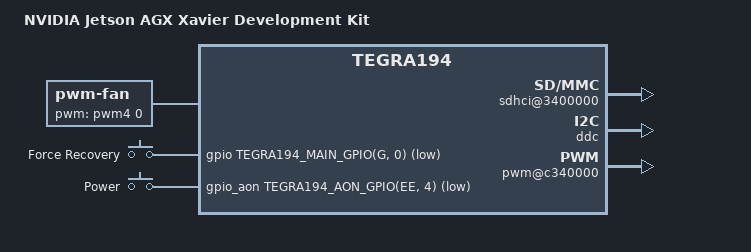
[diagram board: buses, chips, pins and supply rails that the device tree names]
// SPDX-License-Identifier: GPL-2.0
/dts-v1/;

#include <dt-bindings/input/linux-event-codes.h>
#include <dt-bindings/input/gpio-keys.h>

#include "tegra194-p2888.dtsi"

/ {
	model = "NVIDIA Jetson AGX Xavier Development Kit";
	compatible = "nvidia,p2972-0000", "nvidia,tegra194";

	cbb {
		/* SDMMC1 (SD/MMC) */
		sdhci@3400000 {
			status = "okay";
		};

		host1x@13e00000 {
			display-hub@15200000 {
				status = "okay";
			};

			dpaux@155e0000 {
				status = "okay";
			};

			sor@15b80000 {
				status = "okay";

				avdd-io-supply = <&vdd_1v0>;
				vdd-pll-supply = <&vdd_1v8hs>;
				hdmi-supply = <&vdd_hdmi>;

				nvidia,ddc-i2c-bus = <&ddc>;
				nvidia,hpd-gpio = <&gpio TEGRA194_MAIN_GPIO(M, 2) GPIO_ACTIVE_LOW>;
			};
		};

		ddc: i2c@31c0000 {
			status = "okay";
		};

		pwm@c340000 {
			status = "okay";
		};
	};

	fan {
		compatible = "pwm-fan";
		pwms = <&pwm4 0 45334>;
	};

	gpio-keys {
		compatible = "gpio-keys";

		force-recovery {
			label = "Force Recovery";
			gpios = <&gpio TEGRA194_MAIN_GPIO(G, 0)
				       GPIO_ACTIVE_LOW>;
			linux,input-type = <EV_KEY>;
			linux,code = <BTN_1>;
			debounce-interval = <10>;
		};

		power {
			label = "Power";
			gpios = <&gpio_aon TEGRA194_AON_GPIO(EE, 4)
					   GPIO_ACTIVE_LOW>;
			linux,input-type = <EV_KEY>;
			linux,code = <KEY_POWER>;
			debounce-interval = <10>;
			wakeup-event-action = <EV_ACT_ASSERTED>;
			wakeup-source;
		};
	};
};
